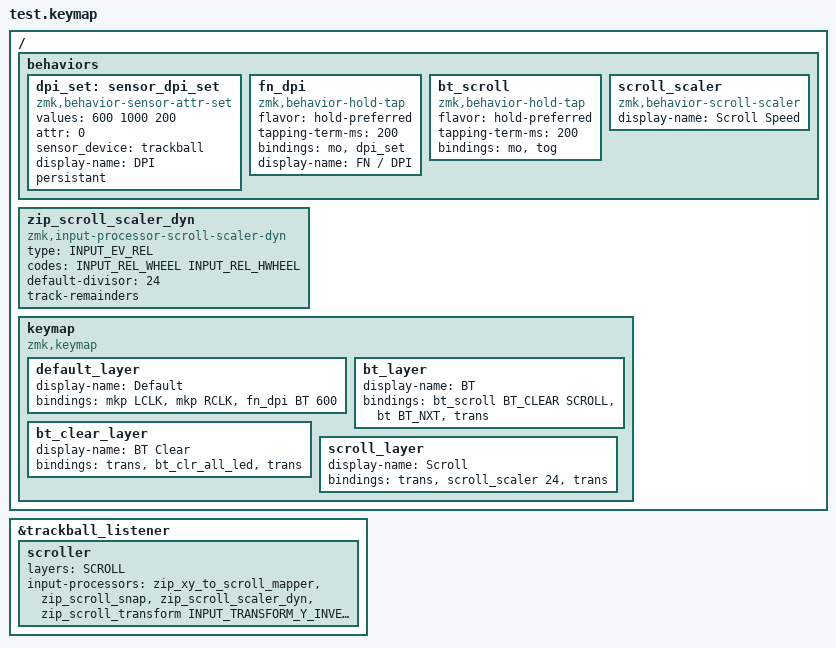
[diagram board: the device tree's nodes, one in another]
#include <behaviors.dtsi>
#include <behaviors/bt_profile_led.dtsi>
#include <dt-bindings/zmk/keys.h>
#include <dt-bindings/zmk/bt.h>
#include <dt-bindings/zmk/pointing.h>
#include <dt-bindings/zmk/input_transform.h>
#include <input/processors.dtsi>
#include <scroll-snap.dtsi>

#define DEFAULT 0
#define BT 1
#define BT_CLEAR 2
#define SCROLL 3

/ {
    behaviors {
        // Physical tap: cycle fixed DPI list (600/1000/200).
        // ZMK Studio Save: immediately applies Param 2 (200..3200, step 200) without a keypress.
        dpi_set: sensor_dpi_set {
            compatible = "zmk,behavior-sensor-attr-set";
            #binding-cells = <1>;
            values = < 600 1000 200 >;
            attr = <0>;
            sensor_device = <&trackball>;
            display-name = "DPI";
            persistant;
        };

        fn_dpi: fn_dpi {
            compatible = "zmk,behavior-hold-tap";
            #binding-cells = <2>;
            flavor = "hold-preferred";
            tapping-term-ms = <200>;
            bindings = <&mo>, <&dpi_set>;
            display-name = "FN / DPI";
        };

        bt_scroll: bt_scroll {
            compatible = "zmk,behavior-hold-tap";
            #binding-cells = <2>;
            flavor = "hold-preferred";
            tapping-term-ms = <200>;
            bindings = <&mo>, <&tog>;
        };

        // ZMK Studio Save: sets dynamic scroll divisor (no-op on physical press)
        scroll_scaler: scroll_scaler {
            compatible = "zmk,behavior-scroll-scaler";
            #binding-cells = <1>;
            display-name = "Scroll Speed";
        };
    };

    zip_scroll_scaler_dyn: zip_scroll_scaler_dyn {
        compatible = "zmk,input-processor-scroll-scaler-dyn";
        #input-processor-cells = <0>;
        type = <INPUT_EV_REL>;
        codes = <INPUT_REL_WHEEL INPUT_REL_HWHEEL>;
        default-divisor = <24>;
        track-remainders;
    };

    keymap {
        compatible = "zmk,keymap";

        default_layer { // Layer 0
            display-name = "Default";
            // -------------
            // |     Z     |
            // |     A     |
            // |     D     |
            bindings = <
                &mkp LCLK
                &mkp RCLK
                &fn_dpi BT 600
            >;
        };

        bt_layer { // Layer 1 (Hold FN)
            display-name = "BT";
            bindings = <
                &bt_scroll BT_CLEAR SCROLL
                &bt BT_NXT
                &trans
            >;
        };

        bt_clear_layer { // Layer 2 (Hold FN + Hold left key)
            display-name = "BT Clear";
            bindings = <
                &trans
                &bt_clr_all_led
                &trans
            >;
        };

        scroll_layer { // Layer 3 (Hold FN + Tap left key)
            display-name = "Scroll";
            bindings = <
                &trans
                &scroll_scaler 24
                &trans
            >;
        };
    };
};

&trackball_listener {
    scroller {
        layers = <SCROLL>;
        input-processors
            = <&zip_xy_to_scroll_mapper>
            , <&zip_scroll_snap>
            , <&zip_scroll_scaler_dyn>
            , <&zip_scroll_transform INPUT_TRANSFORM_Y_INVERT>
            ;
    };
};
